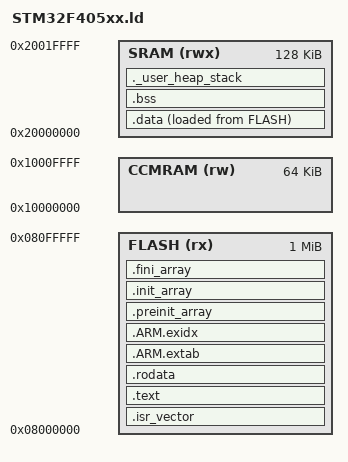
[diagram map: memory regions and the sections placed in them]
/* Linker script for STM32F405xx
 * STM32F405RGT6: FLASH 1024KB, SRAM 128KB, CCMRAM 64KB
 * Adjust memory sizes for your specific part number.
 */

ENTRY(Reset_Handler)

MEMORY
{
    FLASH  (rx)  : ORIGIN = 0x08000000, LENGTH = 1024K
    SRAM   (rwx) : ORIGIN = 0x20000000, LENGTH = 128K
    CCMRAM (rw)  : ORIGIN = 0x10000000, LENGTH = 64K
}

_estack = ORIGIN(SRAM) + LENGTH(SRAM);
_min_heap_size  = 0x200;
_min_stack_size = 0x400;

SECTIONS
{
    .isr_vector :
    {
        . = ALIGN(4);
        KEEP(*(.isr_vector))
        . = ALIGN(4);
    } > FLASH

    .text :
    {
        . = ALIGN(4);
        *(.text)
        *(.text*)
        *(.glue_7)
        *(.glue_7t)
        . = ALIGN(4);
        KEEP(*(.init))
        KEEP(*(.fini))
    } > FLASH

    .rodata :
    {
        . = ALIGN(4);
        *(.rodata)
        *(.rodata*)
        . = ALIGN(4);
    } > FLASH

    .ARM.extab :
    {
        . = ALIGN(4);
        *(.ARM.extab* .gnu.linkonce.armextab.*)
    } > FLASH

    .ARM.exidx :
    {
        . = ALIGN(4);
        PROVIDE(__exidx_start = .);
        *(.ARM.exidx* .gnu.linkonce.armexidx.*)
        PROVIDE(__exidx_end = .);
    } > FLASH

    .preinit_array :
    {
        . = ALIGN(4);
        PROVIDE_HIDDEN(__preinit_array_start = .);
        KEEP(*(.preinit_array*))
        PROVIDE_HIDDEN(__preinit_array_end = .);
    } > FLASH

    .init_array :
    {
        . = ALIGN(4);
        PROVIDE_HIDDEN(__init_array_start = .);
        KEEP(*(SORT(.init_array.*)))
        KEEP(*(.init_array*))
        PROVIDE_HIDDEN(__init_array_end = .);
    } > FLASH

    .fini_array :
    {
        . = ALIGN(4);
        PROVIDE_HIDDEN(__fini_array_start = .);
        KEEP(*(SORT(.fini_array.*)))
        KEEP(*(.fini_array*))
        PROVIDE_HIDDEN(__fini_array_end = .);
    } > FLASH

    _sidata = LOADADDR(.data);

    .data :
    {
        . = ALIGN(4);
        _sdata = .;
        *(.data)
        *(.data*)
        . = ALIGN(4);
        _edata = .;
    } > SRAM AT > FLASH

    .bss (NOLOAD) :
    {
        . = ALIGN(4);
        _sbss = .;
        *(.bss)
        *(.bss*)
        *(COMMON)
        . = ALIGN(4);
        _ebss = .;
    } > SRAM

    ._user_heap_stack (NOLOAD) :
    {
        . = ALIGN(8);
        PROVIDE(end = .);
        PROVIDE(_end = .);
        . = . + _min_heap_size;
        . = . + _min_stack_size;
        . = ALIGN(8);
    } > SRAM

    /DISCARD/ :
    {
        libc.a(*)
        libm.a(*)
        libgcc.a(*)
    }
}
